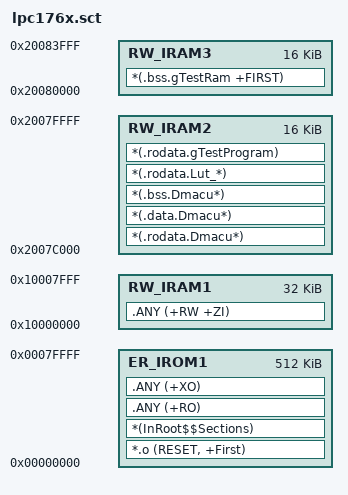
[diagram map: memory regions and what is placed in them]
;
; Scatter-loading descriptor for the LPC176x C
;
; Adapted from uVision generated scatter-loading description file
; to accomodate for compact placement of DMACU content.

LR_IROM1 0x00000000 0x000080000
{
  ER_IROM1 0x00000000 0x80000
  {
   *.o (RESET, +First)
   *(InRoot$$Sections)
   .ANY (+RO)
   .ANY (+XO)
  }

  RW_IRAM1 0x10000000 0x00008000
  {
	; Normal (ARM-side) content
	.ANY (+RW +ZI)
  }

  RW_IRAM2 0x2007C000 0x00004000
  {
	; DMACU descriptors (we let the scatter-loader load all
	; patchable and read-only descriptors to this segment to
	; minimize interference with the ARM CPU and the flash).
	;
	; NOTE: Placement of our DMA descriptors in the AHB SRAM allows
	; the PL080 controller to resume operating while the CPU is in WFE.
	; (cf. [UM10360; "4.8.1 Sleep Mode"])
	;
	*(.rodata.Dmacu*)
	*(.data.Dmacu*)
	*(.bss.Dmacu*)

	; Lookup tables
	*(.rodata.Lut_*)

	; Test program (flash is not accessible in sleep mode - i.e. during WFE)
	*(.rodata.gTestProgram)
  }

  RW_IRAM3 0x20080000 0x00004000
  {
	; RAM segment for the DMACU is placed at a 64k boundary
	*(.bss.gTestRam +FIRST)
  }
}
